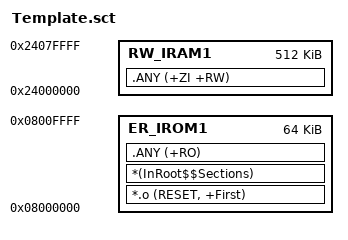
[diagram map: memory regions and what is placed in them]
; *************************************************************
; *** Scatter-Loading Description File generated by uVision ***
; *************************************************************


LR_IROM1 0x08000000 0x00010000  {    ; load region size_region
  ER_IROM1 0x08000000 0x00010000  {  ; load address = execution address
  *.o (RESET, +First)
  *(InRoot$$Sections)
  .ANY (+RO)
  }
  
  RW_IRAM1 0x24000000 0x00080000  {
	.ANY (+ZI +RW)
  }
}

;LR_IROM2 0x08010000 0x00010000 {
;  ER_IROM2 0x00000000 0x00010000{
;  *.o (RESET_ram,+First)
;  startup_stm32h743xx_ram.o (+RO)
;  stm32h7xx_it.o(+RO)
;  stm32h7xx_hal.o (+RO)
;  stm32h7xx_hal_gpio.o (+RO)
;  stm32h7xx_hal_rcc.o (+RO)
;  stm32h7xx_hal_cortex.o(+RO)
;  timer.o(+RO)
;  quicklz.o (+RO)
;  logcompress.o (+RO)
   
; }
  
  
;  RW_IRAM1 0x20000000 0x00001000 {
;	
;	.ANY (+RW)
;  }
;}

